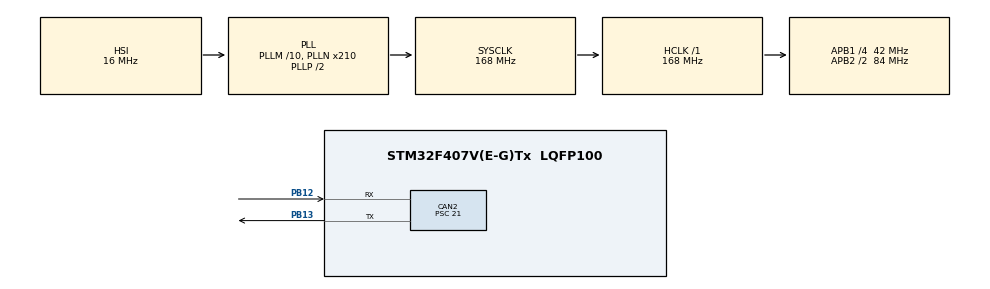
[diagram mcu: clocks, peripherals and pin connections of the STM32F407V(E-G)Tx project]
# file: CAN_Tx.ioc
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CAN2.BS1=CAN_BS1_13TQ
CAN2.BS2=CAN_BS2_2TQ
CAN2.CalculateBaudRate=125000
CAN2.CalculateTimeBit=8000
CAN2.CalculateTimeQuantum=500.0
CAN2.NART=ENABLE
CAN2.Prescaler=21
CAN2.SJW=CAN_SJW_1TQ
Mcu.Family=STM32F4
Mcu.Name=STM32F407V(E-G)Tx
Mcu.Package=LQFP100
NVIC.CAN2_RX0_IRQn=true\:0\:0\:false\:true\:true\:2\:true\:true\:true
NVIC.CAN2_TX_IRQn=true\:0\:0\:false\:true\:true\:1\:true\:true\:true
NVIC.PriorityGroup=NVIC_PRIORITYGROUP_4
NVIC.TIM7_IRQn=true\:0\:0\:false\:false\:true\:true\:true\:true
PB12.Mode=CAN_Activate
PB12.Signal=CAN2_RX
PB13.Mode=CAN_Activate
PB13.Signal=CAN2_TX
ProjectManager.HeapSize=0x200
ProjectManager.StackSize=0x400
ProjectManager.TargetToolchain=STM32CubeIDE
RCC.48MHZClocksFreq_Value=84000000
RCC.AHBFreq_Value=168000000
RCC.APB1CLKDivider=RCC_HCLK_DIV4
RCC.APB1Freq_Value=42000000
RCC.APB1TimFreq_Value=84000000
RCC.APB2CLKDivider=RCC_HCLK_DIV2
RCC.APB2Freq_Value=84000000
RCC.APB2TimFreq_Value=168000000
RCC.CortexFreq_Value=168000000
RCC.HCLKFreq_Value=168000000
RCC.HSE_VALUE=25000000
RCC.HSI_VALUE=16000000
RCC.LSE_VALUE=32768
RCC.PLLM=10
RCC.PLLN=210
RCC.SYSCLKFreq_VALUE=168000000
RCC.SYSCLKSource=RCC_SYSCLKSOURCE_PLLCLK
RCC.VCOOutputFreq_Value=336000000
TIM7.AutoReloadPreload=TIM_AUTORELOAD_PRELOAD_ENABLE
TIM7.Period=6000
TIM7.Prescaler=60000
VP_TIM7_VS_ClockSourceINT.Mode=Enable_Timer
board=custom

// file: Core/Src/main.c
/* USER CODE BEGIN Header */
/**
  ******************************************************************************
  * @file           : main.c
  * @brief          : Main program body
  ******************************************************************************
  * @attention
  *
  * Copyright (c) 2023 STMicroelectronics.
  * All rights reserved.
  *
  * This software is licensed under terms that can be found in the LICENSE file
  * in the root directory of this software component.
  * If no LICENSE file comes with this software, it is provided AS-IS.
  *
  ******************************************************************************
  */
/* USER CODE END Header */
#include "main.h"

/* USER CODE BEGIN Includes */
#include "stm32f4xx_hal.h"
/* USER CODE END Includes */

/* USER CODE BEGIN PTD */

CAN_TxHeaderTypeDef TxHeader;
uint8_t TxData[8];
uint32_t TxMailbox;

/* USER CODE END PTD */

CAN_HandleTypeDef hcan2;

TIM_HandleTypeDef htim7;

void SystemClock_Config(void);
static void MX_GPIO_Init(void);
static void MX_CAN2_Init(void);
static void MX_TIM7_Init(void);
static void MX_NVIC_Init(void);

int main(void)
{

  /* MCU Configuration--------------------------------------------------------*/

  /* Reset of all peripherals, Initializes the Flash interface and the Systick. */
  HAL_Init();

  /* Configure the system clock */
  SystemClock_Config();

  /* Initialize all configured peripherals */
  MX_GPIO_Init();
  MX_CAN2_Init();
  MX_TIM7_Init();

  /* Initialize interrupts */
  MX_NVIC_Init();
  /* USER CODE BEGIN 2 */

	if (HAL_CAN_Start(&hcan2) != HAL_OK)
	{
		/* Start Error */
		Error_Handler();
	}

   /* Configure Transmission process */
   TxHeader.StdId = 0x02;                 // Standard Identifier, 0 ~ 0x7FF
   TxHeader.ExtId = 0;                  // Extended Identifier, 0 ~ 0x1FFFFFFF
   TxHeader.RTR = CAN_RTR_DATA;            // DATA or REMOTE
   TxHeader.IDE = CAN_ID_STD;              // STD or EXT
   TxHeader.DLC = 8;                       // 0 ~ 8 byte
   TxHeader.TransmitGlobalTime = DISABLE;  // timestamp counter 값을 capture.

   /* Set the data to be transmitted */
   TxData[0] = 1;
   TxData[1] = 2;
   TxData[2] = 3;
   TxData[3] = 4;
   TxData[4] = 5;
   TxData[5] = 6;
   TxData[6] = 7;
   TxData[7] = 8;

  /* USER CODE END 2 */

  /* Infinite loop */
  while (1)
  {

  }
}

void SystemClock_Config(void)
{
  RCC_OscInitTypeDef RCC_OscInitStruct = {0};
  RCC_ClkInitTypeDef RCC_ClkInitStruct = {0};

  /** Configure the main internal regulator output voltage
  */
  __HAL_RCC_PWR_CLK_ENABLE();
  __HAL_PWR_VOLTAGESCALING_CONFIG(PWR_REGULATOR_VOLTAGE_SCALE1);

  /** Initializes the RCC Oscillators according to the specified parameters
  * in the RCC_OscInitTypeDef structure.
  */
  RCC_OscInitStruct.OscillatorType = RCC_OSCILLATORTYPE_HSI;
  RCC_OscInitStruct.HSIState = RCC_HSI_ON;
  RCC_OscInitStruct.HSICalibrationValue = RCC_HSICALIBRATION_DEFAULT;
  RCC_OscInitStruct.PLL.PLLState = RCC_PLL_ON;
  RCC_OscInitStruct.PLL.PLLSource = RCC_PLLSOURCE_HSI;
  RCC_OscInitStruct.PLL.PLLM = 10;
  RCC_OscInitStruct.PLL.PLLN = 210;
  RCC_OscInitStruct.PLL.PLLP = RCC_PLLP_DIV2;
  RCC_OscInitStruct.PLL.PLLQ = 4;
  if (HAL_RCC_OscConfig(&RCC_OscInitStruct) != HAL_OK)
  {
    Error_Handler();
  }

  /** Initializes the CPU, AHB and APB buses clocks
  */
  RCC_ClkInitStruct.ClockType = RCC_CLOCKTYPE_HCLK|RCC_CLOCKTYPE_SYSCLK
                              |RCC_CLOCKTYPE_PCLK1|RCC_CLOCKTYPE_PCLK2;
  RCC_ClkInitStruct.SYSCLKSource = RCC_SYSCLKSOURCE_PLLCLK;
  RCC_ClkInitStruct.AHBCLKDivider = RCC_SYSCLK_DIV1;
  RCC_ClkInitStruct.APB1CLKDivider = RCC_HCLK_DIV4;
  RCC_ClkInitStruct.APB2CLKDivider = RCC_HCLK_DIV2;

  if (HAL_RCC_ClockConfig(&RCC_ClkInitStruct, FLASH_LATENCY_5) != HAL_OK)
  {
    Error_Handler();
  }
}

/**
  * @brief NVIC Configuration.
  * @retval None
  */
static void MX_NVIC_Init(void)
{
  /* CAN2_TX_IRQn interrupt configuration */
  HAL_NVIC_SetPriority(CAN2_TX_IRQn, 0, 0);
  HAL_NVIC_EnableIRQ(CAN2_TX_IRQn);
  /* CAN2_RX0_IRQn interrupt configuration */
  HAL_NVIC_SetPriority(CAN2_RX0_IRQn, 0, 0);
  HAL_NVIC_EnableIRQ(CAN2_RX0_IRQn);
}

static void MX_CAN2_Init(void)
{

  hcan2.Instance = CAN2;
  hcan2.Init.Prescaler = 21;
  hcan2.Init.Mode = CAN_MODE_NORMAL;
  hcan2.Init.SyncJumpWidth = CAN_SJW_1TQ;
  hcan2.Init.TimeSeg1 = CAN_BS1_13TQ;
  hcan2.Init.TimeSeg2 = CAN_BS2_2TQ;
  hcan2.Init.TimeTriggeredMode = DISABLE;
  hcan2.Init.AutoBusOff = DISABLE;
  hcan2.Init.AutoWakeUp = DISABLE;
  hcan2.Init.AutoRetransmission = ENABLE;
  hcan2.Init.ReceiveFifoLocked = DISABLE;
  hcan2.Init.TransmitFifoPriority = DISABLE;
  if (HAL_CAN_Init(&hcan2) != HAL_OK)
  {
    Error_Handler();
  }

}

static void MX_TIM7_Init(void)
{

  TIM_MasterConfigTypeDef sMasterConfig = {0};

  htim7.Instance = TIM7;
  htim7.Init.Prescaler = 60000;
  htim7.Init.CounterMode = TIM_COUNTERMODE_UP;
  htim7.Init.Period = 6000;
  htim7.Init.AutoReloadPreload = TIM_AUTORELOAD_PRELOAD_ENABLE;
  if (HAL_TIM_Base_Init(&htim7) != HAL_OK)
  {
    Error_Handler();
  }
  sMasterConfig.MasterOutputTrigger = TIM_TRGO_RESET;
  sMasterConfig.MasterSlaveMode = TIM_MASTERSLAVEMODE_DISABLE;
  if (HAL_TIMEx_MasterConfigSynchronization(&htim7, &sMasterConfig) != HAL_OK)
  {
    Error_Handler();
  }
  /* USER CODE BEGIN TIM7_Init 2 */
  HAL_TIM_Base_Start_IT(&htim7);
  /* USER CODE END TIM7_Init 2 */

}

static void MX_GPIO_Init(void)
{

  /* GPIO Ports Clock Enable */
  __HAL_RCC_GPIOB_CLK_ENABLE();

}

void Error_Handler(void)
{
  __disable_irq();
  while (1)
  {
  }
}
